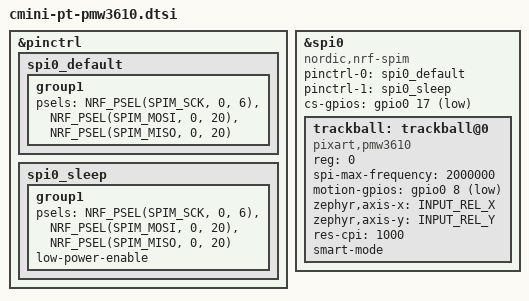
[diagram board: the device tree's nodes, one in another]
#include <zephyr/dt-bindings/input/input-event-codes.h>

/* Both halves use the original right-hand PMW3610 wiring. */
&pinctrl {
    spi0_default: spi0_default {
        group1 {
            psels = <NRF_PSEL(SPIM_SCK, 0, 6)>,
                    <NRF_PSEL(SPIM_MOSI, 0, 20)>,
                    <NRF_PSEL(SPIM_MISO, 0, 20)>;
        };
    };

    spi0_sleep: spi0_sleep {
        group1 {
            psels = <NRF_PSEL(SPIM_SCK, 0, 6)>,
                    <NRF_PSEL(SPIM_MOSI, 0, 20)>,
                    <NRF_PSEL(SPIM_MISO, 0, 20)>;
            low-power-enable;
        };
    };
};

&spi0 {
    status = "okay";
    compatible = "nordic,nrf-spim";
    pinctrl-0 = <&spi0_default>;
    pinctrl-1 = <&spi0_sleep>;
    pinctrl-names = "default", "sleep";
    cs-gpios = <&gpio0 17 GPIO_ACTIVE_LOW>;

    trackball: trackball@0 {
        compatible = "pixart,pmw3610";
        status = "okay";
        reg = <0>;
        spi-max-frequency = <2000000>;
        motion-gpios = <&gpio0 8 (GPIO_ACTIVE_LOW | GPIO_PULL_UP)>;
        zephyr,axis-x = <INPUT_REL_X>;
        zephyr,axis-y = <INPUT_REL_Y>;
        res-cpi = <1000>;
        smart-mode;
    };
};
